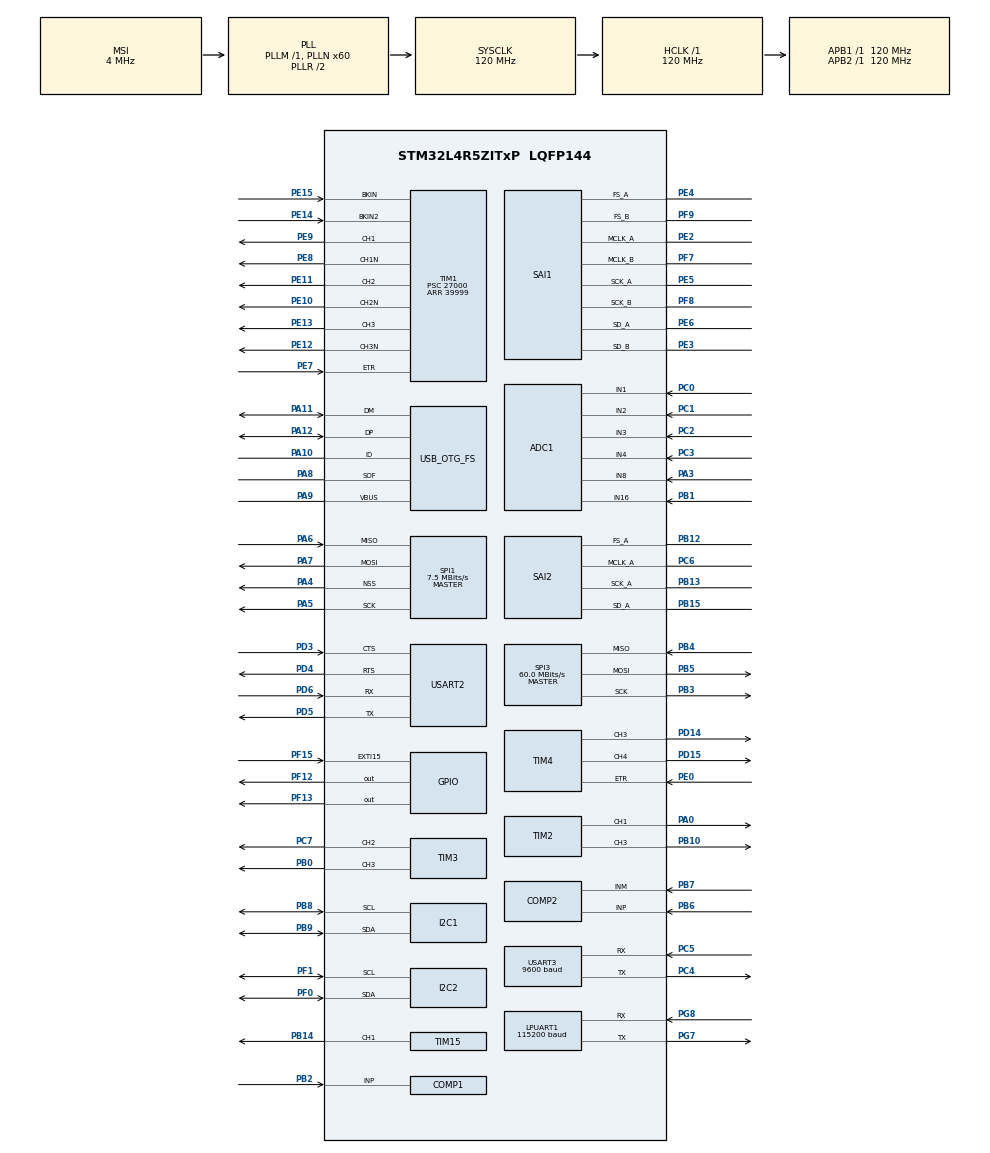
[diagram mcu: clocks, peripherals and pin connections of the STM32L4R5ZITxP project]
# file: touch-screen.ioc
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ADC1.Channel-0\#ChannelRegularConversion=ADC_CHANNEL_1
ADC1.NbrOfConversionFlag=1
ADC1.OffsetNumber-0\#ChannelRegularConversion=ADC_OFFSET_NONE
ADC1.Rank-0\#ChannelRegularConversion=1
ADC1.SamplingTime-0\#ChannelRegularConversion=ADC_SAMPLETIME_2CYCLES_5
ADC1.master=1
I2C1.Speed=100
I2C1.Timing=0x307075B1
I2C2.Timing=0x307075B1
LPUART1.BaudRate=115200
LPUART1.WordLength=UART_WORDLENGTH_8B
Mcu.Family=STM32L4
Mcu.Name=STM32L4R5ZITxP
Mcu.Package=LQFP144
NVIC.EXTI15_10_IRQn=true\:0\:0\:false\:false\:true\:true\:true\:true
NVIC.PriorityGroup=NVIC_PRIORITYGROUP_4
NVIC.TIM1_UP_TIM16_IRQn=true\:0\:0\:false\:false\:true\:true\:true\:true
NVIC.USART3_IRQn=true\:0\:0\:false\:false\:true\:true\:true\:true
PA0.Signal=S_TIM2_CH1
PA10.Mode=OTG/Dual_Role_Device
PA10.Signal=USB_OTG_FS_ID
PA11.Mode=OTG/Dual_Role_Device
PA11.Signal=USB_OTG_FS_DM
PA12.Mode=OTG/Dual_Role_Device
PA12.Signal=USB_OTG_FS_DP
PA13\ (JTMS/SWDIO).Mode=Serial_Wire
PA13\ (JTMS/SWDIO).Signal=SYS_JTMS-SWDIO
PA14\ (JTCK/SWCLK).Mode=Serial_Wire
PA14\ (JTCK/SWCLK).Signal=SYS_JTCK-SWCLK
PA3.Signal=ADCx_IN8
PA4.Mode=NSS_Signal_Hard_Output
PA4.Signal=SPI1_NSS
PA5.Mode=Full_Duplex_Master
PA5.Signal=SPI1_SCK
PA6.Mode=Full_Duplex_Master
PA6.Signal=SPI1_MISO
PA7.Mode=Full_Duplex_Master
PA7.Signal=SPI1_MOSI
PA8.Mode=Activate_SOF_FS
PA8.Signal=USB_OTG_FS_SOF
PA9.Mode=Activate_VBUS
PA9.Signal=USB_OTG_FS_VBUS
PB0.Signal=S_TIM3_CH3
PB1.Signal=ADCx_IN16
PB10.Signal=S_TIM2_CH3
PB12.Mode=SAI_A_MasterWithClock
PB12.Signal=SAI2_FS_A
PB13.Mode=SAI_A_MasterWithClock
PB13.Signal=SAI2_SCK_A
PB14.Signal=S_TIM15_CH1
PB15.Mode=SAI_A_MasterWithClock
PB15.Signal=SAI2_SD_A
PB2.Mode=INP
PB2.Signal=COMP1_INP
PB3\ (JTDO/TRACESWO).Mode=Full_Duplex_Master
PB3\ (JTDO/TRACESWO).Signal=SPI3_SCK
PB4\ (NJTRST).Mode=Full_Duplex_Master
PB4\ (NJTRST).Signal=SPI3_MISO
PB5.Mode=Full_Duplex_Master
PB5.Signal=SPI3_MOSI
PB6.Mode=INP
PB6.Signal=COMP2_INP
PB7.Mode=INM
PB7.Signal=COMP2_INM
PB8.GPIO_Pu=GPIO_PULLUP
PB8.Mode=I2C
PB8.Signal=I2C1_SCL
PB9.GPIO_Pu=GPIO_PULLUP
PB9.Mode=I2C
PB9.Signal=I2C1_SDA
PC0.Signal=ADCx_IN1
PC1.Signal=ADCx_IN2
PC13.Mode=SYS_WakeUp1
PC13.Signal=SYS_WKUP2
PC14-OSC32_IN\ (PC14).Mode=LSE-External-Oscillator
PC14-OSC32_IN\ (PC14).Signal=RCC_OSC32_IN
PC15-OSC32_OUT\ (PC15).Mode=LSE-External-Oscillator
PC15-OSC32_OUT\ (PC15).Signal=RCC_OSC32_OUT
PC2.Signal=ADCx_IN3
PC3.Signal=ADCx_IN4
PC4.Mode=Asynchronous
PC4.Signal=USART3_TX
PC5.Mode=Asynchronous
PC5.Signal=USART3_RX
PC6.Mode=SAI_A_MasterWithClock
PC6.Signal=SAI2_MCLK_A
PC7.Signal=S_TIM3_CH2
PD14.Signal=S_TIM4_CH3
PD15.Signal=S_TIM4_CH4
PD3.Mode=CTS_RTS
PD3.Signal=USART2_CTS
PD4.Mode=CTS_RTS
PD4.Signal=USART2_RTS
PD5.Mode=Asynchronous
PD5.Signal=USART2_TX
PD6.Mode=Asynchronous
PD6.Signal=USART2_RX
PE0.Signal=S_TIM4_ETR
PE10.Mode=PWM Generation2 CH2 CH2N
PE10.Signal=TIM1_CH2N
PE11.Signal=S_TIM1_CH2
PE12.Mode=PWM Generation3 CH3 CH3N
PE12.Signal=TIM1_CH3N
PE13.Signal=S_TIM1_CH3
PE14.Mode=Activate-Break-Input-2
PE14.Signal=TIM1_BKIN2
PE15.Mode=Activate-Break-Input
PE15.Signal=TIM1_BKIN
PE2.Mode=SAI_A_MasterWithClock
PE2.Signal=SAI1_MCLK_A
PE3.Mode=SAI_B_MasterWithClock
PE3.Signal=SAI1_SD_B
PE4.Mode=SAI_A_MasterWithClock
PE4.Signal=SAI1_FS_A
PE5.Mode=SAI_A_MasterWithClock
PE5.Signal=SAI1_SCK_A
PE6.Mode=SAI_A_MasterWithClock
PE6.Signal=SAI1_SD_A
PE7.Signal=S_TIM1_ETR
PE8.Mode=PWM Generation1 CH1 CH1N
PE8.Signal=TIM1_CH1N
PE9.Signal=S_TIM1_CH1
PF0.Mode=I2C
PF0.Signal=I2C2_SDA
PF1.Mode=I2C
PF1.Signal=I2C2_SCL
PF12.Signal=GPIO_Output
PF13.Signal=GPIO_Output
PF15.GPIO_ModeDefaultEXTI=GPIO_MODE_IT_FALLING
PF15.Signal=GPXTI15
PF7.Mode=SAI_B_MasterWithClock
PF7.Signal=SAI1_MCLK_B
PF8.Mode=SAI_B_MasterWithClock
PF8.Signal=SAI1_SCK_B
PF9.Mode=SAI_B_MasterWithClock
PF9.Signal=SAI1_FS_B
PG7.Mode=Asynchronous
PG7.Signal=LPUART1_TX
PG8.Mode=Asynchronous
PG8.Signal=LPUART1_RX
PH0-OSC_IN\ (PH0).Mode=HSE-External-Oscillator
PH0-OSC_IN\ (PH0).Signal=RCC_OSC_IN
PH1-OSC_OUT\ (PH1).Mode=HSE-External-Oscillator
PH1-OSC_OUT\ (PH1).Signal=RCC_OSC_OUT
ProjectManager.HeapSize=0x200
ProjectManager.StackSize=0x400
ProjectManager.TargetToolchain=STM32CubeIDE
RCC.ADCFreq_Value=48000000
RCC.AHBFreq_Value=120000000
RCC.APB1Freq_Value=120000000
RCC.APB1TimFreq_Value=120000000
RCC.APB2Freq_Value=120000000
RCC.APB2TimFreq_Value=120000000
RCC.CortexFreq_Value=120000000
RCC.HCLKFreq_Value=120000000
RCC.HSE_VALUE=8000000
RCC.HSI48_VALUE=48000000
RCC.HSI_VALUE=16000000
RCC.MSI_VALUE=4000000
RCC.PLLN=60
RCC.PLLSAI1N=24
RCC.SYSCLKFreq_VALUE=120000000
RCC.SYSCLKSource=RCC_SYSCLKSOURCE_PLLCLK
RCC.USBFreq_Value=48000000
RCC.VCOOutputFreq_Value=240000000
SAI1.InitProtocol-SAI_A_MasterWithClock=Enable
SAI1.Instance-SAI_A_MasterWithClock=SAI$Index_Block_A
SAI1.Instance-SAI_B_MasterWithClock=SAI$Index_Block_B
SAI1.MClockEnable-SAI_A_MasterWithClock=SAI_MASTERCLOCK_ENABLE
SAI1.MClockEnable-SAI_B_MasterWithClock=SAI_MASTERCLOCK_ENABLE
SAI1.Synchro-SAI_A_MasterWithClock=SAI_ASYNCHRONOUS
SAI1.Synchro-SAI_B_MasterWithClock=SAI_ASYNCHRONOUS
SAI1.VirtualMode-SAI_A_MasterWithClock=VM_MASTER
SAI1.VirtualMode-SAI_B_MasterWithClock=VM_MASTER
SAI1.VirtualProtocol-SAI_A_BASIC=VM_BASIC_PROTOCOL
SAI2.Instance-SAI_A_MasterWithClock=SAI$Index_Block_A
SAI2.MClockEnable-SAI_A_MasterWithClock=SAI_MASTERCLOCK_ENABLE
SAI2.Synchro-SAI_A_MasterWithClock=SAI_ASYNCHRONOUS
SAI2.VirtualMode-SAI_A_MasterWithClock=VM_MASTER
SH.ADCx_IN1.0=ADC1_IN1,IN1-Single-Ended
SH.ADCx_IN16.0=ADC1_IN16,IN16-Single-Ended
SH.ADCx_IN2.0=ADC1_IN2,IN2-Single-Ended
SH.ADCx_IN3.0=ADC1_IN3,IN3-Single-Ended
SH.ADCx_IN4.0=ADC1_IN4,IN4-Single-Ended
SH.ADCx_IN8.0=ADC1_IN8,IN8-Single-Ended
SH.S_TIM15_CH1.0=TIM15_CH1,PWM Generation1 CH1
SH.S_TIM1_CH1.0=TIM1_CH1,PWM Generation1 CH1 CH1N
SH.S_TIM1_CH2.0=TIM1_CH2,PWM Generation2 CH2 CH2N
SH.S_TIM1_CH3.0=TIM1_CH3,PWM Generation3 CH3 CH3N
SH.S_TIM1_ETR.0=TIM1_ETR,ETR-as-clearing-source
SH.S_TIM2_CH1.0=TIM2_CH1,PWM Generation1 CH1
SH.S_TIM2_CH3.0=TIM2_CH3,PWM Generation3 CH3
SH.S_TIM3_CH2.0=TIM3_CH2,PWM Generation2 CH2
SH.S_TIM3_CH3.0=TIM3_CH3,PWM Generation3 CH3
SH.S_TIM4_CH3.0=TIM4_CH3,PWM Generation3 CH3
SH.S_TIM4_CH4.0=TIM4_CH4,PWM Generation4 CH4
SH.S_TIM4_ETR.0=TIM4_ETR,ETR-as-clearing-source
SPI1.BaudRatePrescaler=SPI_BAUDRATEPRESCALER_16
SPI1.CalculateBaudRate=7.5 MBits/s
SPI1.DataSize=SPI_DATASIZE_8BIT
SPI1.Direction=SPI_DIRECTION_2LINES
SPI1.Mode=SPI_MODE_MASTER
SPI1.VirtualNSS=VM_NSSHARD
SPI1.VirtualType=VM_MASTER
SPI3.CalculateBaudRate=60.0 MBits/s
SPI3.Direction=SPI_DIRECTION_2LINES
SPI3.Mode=SPI_MODE_MASTER
SPI3.VirtualType=VM_MASTER
TIM1.Channel-PWM\ Generation1\ CH1\ CH1N=TIM_CHANNEL_1
TIM1.Channel-PWM\ Generation2\ CH2\ CH2N=TIM_CHANNEL_2
TIM1.Channel-PWM\ Generation3\ CH3\ CH3N=TIM_CHANNEL_3
TIM1.Period=39999
TIM1.Prescaler=27000
TIM15.Channel-PWM\ Generation1\ CH1=TIM_CHANNEL_1
TIM2.Channel-PWM\ Generation1\ CH1=TIM_CHANNEL_1
TIM2.Channel-PWM\ Generation3\ CH3=TIM_CHANNEL_3
TIM3.Channel-PWM\ Generation2\ CH2=TIM_CHANNEL_2
TIM3.Channel-PWM\ Generation3\ CH3=TIM_CHANNEL_3
TIM4.Channel-PWM\ Generation3\ CH3=TIM_CHANNEL_3
TIM4.Channel-PWM\ Generation4\ CH4=TIM_CHANNEL_4
USART2.VirtualMode-Asynchronous=VM_ASYNC
USART3.BaudRate=9600
USART3.VirtualMode-Asynchronous=VM_ASYNC
VP_COMP1_VS_VREFINT.Mode=VREFINT
VP_SAI1_VP_$IpInstance_SAIA_SAI_BASIC.Mode=SAI_A_BASIC
VP_TIM1_VS_ClockSourceINT.Mode=Internal
board=NUCLEO-L4R5ZI-P

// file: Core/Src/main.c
/* USER CODE BEGIN Header */
/**
 ******************************************************************************
 * @file           : main.c
 * @brief          : Main program body
 ******************************************************************************
 * @attention
 *
 * Copyright (c) 2024 STMicroelectronics.
 * All rights reserved.
 *
 * This software is licensed under terms that can be found in the LICENSE file
 * in the root directory of this software component.
 * If no LICENSE file comes with this software, it is provided AS-IS.
 *
 ******************************************************************************
 */
/* USER CODE END Header */
#include "main.h"

/* USER CODE BEGIN Includes */
#include "stdio.h"
#include "stdlib.h"
#include "string.h"
#include "foodorder.h"
#include "screen.h"
#include "touch.h"
/* USER CODE END Includes */

/* USER CODE BEGIN PD */
#define RX_BUFFER_SIZE 256
#define MAX_FOOD_ORDERS 5
#define SENSOR_ADDR 0x0C << 1 // Shift left for the HAL library
#define READ_LEN 2            // Start by reading the 16-bit content length
/* USER CODE END PD */

ADC_HandleTypeDef hadc1;

COMP_HandleTypeDef hcomp1;
COMP_HandleTypeDef hcomp2;

I2C_HandleTypeDef hi2c1;
I2C_HandleTypeDef hi2c2;

UART_HandleTypeDef hlpuart1;
UART_HandleTypeDef huart2;
UART_HandleTypeDef huart3;

SAI_HandleTypeDef hsai_BlockB1;
SAI_HandleTypeDef hsai_BlockA1;
SAI_HandleTypeDef hsai_BlockA2;

SPI_HandleTypeDef hspi1;
SPI_HandleTypeDef hspi3;

TIM_HandleTypeDef htim1;
TIM_HandleTypeDef htim2;
TIM_HandleTypeDef htim3;
TIM_HandleTypeDef htim4;
TIM_HandleTypeDef htim15;

/* USER CODE BEGIN PV */
char rxBuffer[RX_BUFFER_SIZE];
FoodOrder foodOrders[MAX_FOOD_ORDERS];
volatile uint16_t rxIndex = 0;
uint32_t i = 0;
/* USER CODE END PV */

void SystemClock_Config(void);
void PeriphCommonClock_Config(void);
static void MX_GPIO_Init(void);
static void MX_ADC1_Init(void);
static void MX_COMP1_Init(void);
static void MX_COMP2_Init(void);
static void MX_I2C1_Init(void);
static void MX_LPUART1_UART_Init(void);
static void MX_USART2_UART_Init(void);
static void MX_USART3_UART_Init(void);
static void MX_SAI1_Init(void);
static void MX_SAI2_Init(void);
static void MX_SPI1_Init(void);
static void MX_SPI3_Init(void);
static void MX_TIM1_Init(void);
static void MX_TIM2_Init(void);
static void MX_TIM3_Init(void);
static void MX_TIM4_Init(void);
static void MX_TIM15_Init(void);
static void MX_USB_OTG_FS_USB_Init(void);
static void MX_I2C2_Init(void);
/* USER CODE BEGIN PFP */
void processReceivedData(char *data);
static void uartSend(char *str);
/* USER CODE END PFP */

/* USER CODE BEGIN 0 */
void readTinyCodeData(void)
{
  uint8_t readBuffer[256]; // Buffer to store the read data
  uint16_t contentLength = 0;

  // First, read the content length
  HAL_StatusTypeDef status = HAL_I2C_Master_Receive(&hi2c2, SENSOR_ADDR, readBuffer, READ_LEN, HAL_MAX_DELAY);
  if (status != HAL_OK)
  {
    // Handle communication error
  }
  else
  {
    // If read is successful, parse the content length
    contentLength = readBuffer[0] | (readBuffer[1] << 8);
    if (contentLength == 0 ||  contentLength > 254)
    {
      return;
    }
    printf("content length %d\n", contentLength);
    if (contentLength > 0 && contentLength <= 254)
    {
      // Now, read the actual content based on the content length
      status = HAL_I2C_Master_Receive(&hi2c2, SENSOR_ADDR, readBuffer, contentLength + 2, HAL_MAX_DELAY);
      if (status != HAL_OK)
      {
        // Handle communication error
      }
      else
      {
        // Data is now in readBuffer[2] to readBuffer[contentLength+1], process it as needed
        // Remember to handle non-UTF-8 or other data safely
        for (int i = 0; i < contentLength; ++i)
        {
          printf("%c", readBuffer[2 + i]);
        }
        printf("\n");
      }
    }
    else
    {
      // No content or content length invalid
    }
  }
}
void HAL_TIM_PeriodElapsedCallback(TIM_HandleTypeDef *htim)
{
  	if(htim->Instance == TIM1){
  		  uartSend("LIST\n");
  		  HAL_UART_Receive_IT(&huart3, (uint8_t*)&rxBuffer[rxIndex], 1);
  	}
}
void HAL_UART_RxCpltCallback(UART_HandleTypeDef *huart)
{
  if (huart->Instance == USART3)
  {
    ++i;
  }
}

void processReceivedData(char *data)
{
  int totalOrders = atoi(data);
  data += 3;
  int processedOrders = 0;
  if (totalOrders == 0)
  {
    return;
  }
  for (int i = 0; i < MAX_FOOD_ORDERS; ++i)
  {
    FoodOrder_Init(&foodOrders[i]);
  }
  while (processedOrders < totalOrders)
  {
    foodOrders[processedOrders].id = atoi(data);
    data += 11;
    strcpy(foodOrders[processedOrders].name, data);
    while (*data != '\0')
    {
      ++data;
    }
    ++data;
    foodOrders[processedOrders].valid = 1;
    ++processedOrders;
  }
  for (int i = 0; i < processedOrders; ++i)
  {
    printf("Name: %s\r\n", foodOrders[i].name);
    printf("id: %d\r\n", foodOrders[i].id);
  }
}
static void uartSend(char *str)
{
	HAL_StatusTypeDef result = HAL_UART_Transmit(&huart3, (uint8_t *)str, strlen(str), 1000);
  if (HAL_OK != result) {
	  printf("USART send failed with code %d.\r\n", result);
  }
}
void HAL_GPIO_EXTI_Callback(uint16_t GPIO_Pin)
{
  touchHook(&hi2c1);
}
/* USER CODE END 0 */

int main(void)
{

  /* USER CODE BEGIN 1 */
  for (int i = 0; i < MAX_FOOD_ORDERS; ++i)
  {
    FoodOrder_Init(&foodOrders[i]);
  }
  /* USER CODE END 1 */

  /* MCU Configuration--------------------------------------------------------*/

  /* Reset of all peripherals, Initializes the Flash interface and the Systick. */
  HAL_Init();

  /* Configure the system clock */
  SystemClock_Config();

/* Configure the peripherals common clocks */
  PeriphCommonClock_Config();

  /* Initialize all configured peripherals */
  MX_GPIO_Init();
  MX_ADC1_Init();
  MX_COMP1_Init();
  MX_COMP2_Init();
  MX_I2C1_Init();
  MX_LPUART1_UART_Init();
  MX_USART2_UART_Init();
  MX_USART3_UART_Init();
  MX_SAI1_Init();
  MX_SAI2_Init();
  MX_SPI1_Init();
  MX_SPI3_Init();
  MX_TIM1_Init();
  MX_TIM2_Init();
  MX_TIM3_Init();
  MX_TIM4_Init();
  MX_TIM15_Init();
  MX_USB_OTG_FS_USB_Init();
  MX_I2C2_Init();
  /* USER CODE BEGIN 2 */
  HAL_TIM_Base_Start_IT(&htim1);
  initialize_screen(&hspi1);
  draw(&hspi1);
  initialize_touch(&hi2c1);

  /* USER CODE END 2 */

  /* Infinite loop */
  /* USER CODE BEGIN WHILE */
  while (1)
  {
    while (i > 0)
    {
      //		  printf("%c", rxBuffer[rxIndex]);
      if (rxBuffer[rxIndex] == '\n' || rxIndex >= RX_BUFFER_SIZE - 1 || rxBuffer[rxIndex] == '\r')
      {
        // Null-terminate the string
        rxBuffer[rxIndex] = '\0';

        // Process received data
        processReceivedData(rxBuffer);

        // Reset index
        rxIndex = 0;
      }
      else
      {
        // Increment index to receive the next byte
        rxIndex++;
      }
      // Prepare to receive the next byte
      HAL_UART_Receive_IT(&huart3, (uint8_t *)&rxBuffer[rxIndex], 1);

      --i;
    }
    readTinyCodeData();
    /* USER CODE END WHILE */

  }
}

void SystemClock_Config(void)
{
  RCC_OscInitTypeDef RCC_OscInitStruct = {0};
  RCC_ClkInitTypeDef RCC_ClkInitStruct = {0};

  /** Configure the main internal regulator output voltage
  */
  if (HAL_PWREx_ControlVoltageScaling(PWR_REGULATOR_VOLTAGE_SCALE1_BOOST) != HAL_OK)
  {
    Error_Handler();
  }

  /** Configure LSE Drive Capability
  */
  HAL_PWR_EnableBkUpAccess();
  __HAL_RCC_LSEDRIVE_CONFIG(RCC_LSEDRIVE_LOW);

  /** Initializes the RCC Oscillators according to the specified parameters
  * in the RCC_OscInitTypeDef structure.
  */
  RCC_OscInitStruct.OscillatorType = RCC_OSCILLATORTYPE_LSE|RCC_OSCILLATORTYPE_MSI;
  RCC_OscInitStruct.LSEState = RCC_LSE_ON;
  RCC_OscInitStruct.MSIState = RCC_MSI_ON;
  RCC_OscInitStruct.MSICalibrationValue = 0;
  RCC_OscInitStruct.MSIClockRange = RCC_MSIRANGE_6;
  RCC_OscInitStruct.PLL.PLLState = RCC_PLL_ON;
  RCC_OscInitStruct.PLL.PLLSource = RCC_PLLSOURCE_MSI;
  RCC_OscInitStruct.PLL.PLLM = 1;
  RCC_OscInitStruct.PLL.PLLN = 60;
  RCC_OscInitStruct.PLL.PLLP = RCC_PLLP_DIV2;
  RCC_OscInitStruct.PLL.PLLQ = RCC_PLLQ_DIV2;
  RCC_OscInitStruct.PLL.PLLR = RCC_PLLR_DIV2;
  if (HAL_RCC_OscConfig(&RCC_OscInitStruct) != HAL_OK)
  {
    Error_Handler();
  }

  /** Initializes the CPU, AHB and APB buses clocks
  */
  RCC_ClkInitStruct.ClockType = RCC_CLOCKTYPE_HCLK|RCC_CLOCKTYPE_SYSCLK
                              |RCC_CLOCKTYPE_PCLK1|RCC_CLOCKTYPE_PCLK2;
  RCC_ClkInitStruct.SYSCLKSource = RCC_SYSCLKSOURCE_PLLCLK;
  RCC_ClkInitStruct.AHBCLKDivider = RCC_SYSCLK_DIV1;
  RCC_ClkInitStruct.APB1CLKDivider = RCC_HCLK_DIV1;
  RCC_ClkInitStruct.APB2CLKDivider = RCC_HCLK_DIV1;

  if (HAL_RCC_ClockConfig(&RCC_ClkInitStruct, FLASH_LATENCY_5) != HAL_OK)
  {
    Error_Handler();
  }

  /** Enable MSI Auto calibration
  */
  HAL_RCCEx_EnableMSIPLLMode();
}

void PeriphCommonClock_Config(void)
{
  RCC_PeriphCLKInitTypeDef PeriphClkInit = {0};

  /** Initializes the peripherals clock
  */
  PeriphClkInit.PeriphClockSelection = RCC_PERIPHCLK_SAI1|RCC_PERIPHCLK_SAI2
                              |RCC_PERIPHCLK_USB|RCC_PERIPHCLK_ADC;
  PeriphClkInit.Sai1ClockSelection = RCC_SAI1CLKSOURCE_PLLSAI1;
  PeriphClkInit.Sai2ClockSelection = RCC_SAI2CLKSOURCE_PLLSAI1;
  PeriphClkInit.AdcClockSelection = RCC_ADCCLKSOURCE_PLLSAI1;
  PeriphClkInit.UsbClockSelection = RCC_USBCLKSOURCE_PLLSAI1;
  PeriphClkInit.PLLSAI1.PLLSAI1Source = RCC_PLLSOURCE_MSI;
  PeriphClkInit.PLLSAI1.PLLSAI1M = 1;
  PeriphClkInit.PLLSAI1.PLLSAI1N = 24;
  PeriphClkInit.PLLSAI1.PLLSAI1P = RCC_PLLP_DIV2;
  PeriphClkInit.PLLSAI1.PLLSAI1Q = RCC_PLLQ_DIV2;
  PeriphClkInit.PLLSAI1.PLLSAI1R = RCC_PLLR_DIV2;
  PeriphClkInit.PLLSAI1.PLLSAI1ClockOut = RCC_PLLSAI1_SAI1CLK|RCC_PLLSAI1_48M2CLK
                              |RCC_PLLSAI1_ADC1CLK;
  if (HAL_RCCEx_PeriphCLKConfig(&PeriphClkInit) != HAL_OK)
  {
    Error_Handler();
  }
}

static void MX_ADC1_Init(void)
{

  ADC_ChannelConfTypeDef sConfig = {0};

  /** Common config
  */
  hadc1.Instance = ADC1;
  hadc1.Init.ClockPrescaler = ADC_CLOCK_ASYNC_DIV1;
  hadc1.Init.Resolution = ADC_RESOLUTION_12B;
  hadc1.Init.DataAlign = ADC_DATAALIGN_RIGHT;
  hadc1.Init.ScanConvMode = ADC_SCAN_DISABLE;
  hadc1.Init.EOCSelection = ADC_EOC_SINGLE_CONV;
  hadc1.Init.LowPowerAutoWait = DISABLE;
  hadc1.Init.ContinuousConvMode = DISABLE;
  hadc1.Init.NbrOfConversion = 1;
  hadc1.Init.DiscontinuousConvMode = DISABLE;
  hadc1.Init.ExternalTrigConv = ADC_SOFTWARE_START;
  hadc1.Init.ExternalTrigConvEdge = ADC_EXTERNALTRIGCONVEDGE_NONE;
  hadc1.Init.DMAContinuousRequests = DISABLE;
  hadc1.Init.Overrun = ADC_OVR_DATA_PRESERVED;
  hadc1.Init.OversamplingMode = DISABLE;
  if (HAL_ADC_Init(&hadc1) != HAL_OK)
  {
    Error_Handler();
  }

  /** Configure Regular Channel
  */
  sConfig.Channel = ADC_CHANNEL_1;
  sConfig.Rank = ADC_REGULAR_RANK_1;
  sConfig.SamplingTime = ADC_SAMPLETIME_2CYCLES_5;
  sConfig.SingleDiff = ADC_SINGLE_ENDED;
  sConfig.OffsetNumber = ADC_OFFSET_NONE;
  sConfig.Offset = 0;
  if (HAL_ADC_ConfigChannel(&hadc1, &sConfig) != HAL_OK)
  {
    Error_Handler();
  }

}

static void MX_COMP1_Init(void)
{

  hcomp1.Instance = COMP1;
  hcomp1.Init.InvertingInput = COMP_INPUT_MINUS_VREFINT;
  hcomp1.Init.NonInvertingInput = COMP_INPUT_PLUS_IO2;
  hcomp1.Init.OutputPol = COMP_OUTPUTPOL_NONINVERTED;
  hcomp1.Init.Hysteresis = COMP_HYSTERESIS_NONE;
  hcomp1.Init.BlankingSrce = COMP_BLANKINGSRC_NONE;
  hcomp1.Init.Mode = COMP_POWERMODE_HIGHSPEED;
  hcomp1.Init.WindowMode = COMP_WINDOWMODE_DISABLE;
  hcomp1.Init.TriggerMode = COMP_TRIGGERMODE_NONE;
  if (HAL_COMP_Init(&hcomp1) != HAL_OK)
  {
    Error_Handler();
  }

}

static void MX_COMP2_Init(void)
{

  hcomp2.Instance = COMP2;
  hcomp2.Init.InvertingInput = COMP_INPUT_MINUS_IO2;
  hcomp2.Init.NonInvertingInput = COMP_INPUT_PLUS_IO2;
  hcomp2.Init.OutputPol = COMP_OUTPUTPOL_NONINVERTED;
  hcomp2.Init.Hysteresis = COMP_HYSTERESIS_NONE;
  hcomp2.Init.BlankingSrce = COMP_BLANKINGSRC_NONE;
  hcomp2.Init.Mode = COMP_POWERMODE_HIGHSPEED;
  hcomp2.Init.WindowMode = COMP_WINDOWMODE_DISABLE;
  hcomp2.Init.TriggerMode = COMP_TRIGGERMODE_NONE;
  if (HAL_COMP_Init(&hcomp2) != HAL_OK)
  {
    Error_Handler();
  }

}

static void MX_I2C1_Init(void)
{

  hi2c1.Instance = I2C1;
  hi2c1.Init.Timing = 0x307075B1;
  hi2c1.Init.OwnAddress1 = 0;
  hi2c1.Init.AddressingMode = I2C_ADDRESSINGMODE_7BIT;
  hi2c1.Init.DualAddressMode = I2C_DUALADDRESS_DISABLE;
  hi2c1.Init.OwnAddress2 = 0;
  hi2c1.Init.OwnAddress2Masks = I2C_OA2_NOMASK;
  hi2c1.Init.GeneralCallMode = I2C_GENERALCALL_DISABLE;
  hi2c1.Init.NoStretchMode = I2C_NOSTRETCH_DISABLE;
  if (HAL_I2C_Init(&hi2c1) != HAL_OK)
  {
    Error_Handler();
  }

  /** Configure Analogue filter
  */
  if (HAL_I2CEx_ConfigAnalogFilter(&hi2c1, I2C_ANALOGFILTER_ENABLE) != HAL_OK)
  {
    Error_Handler();
  }

  /** Configure Digital filter
  */
  if (HAL_I2CEx_ConfigDigitalFilter(&hi2c1, 0) != HAL_OK)
  {
    Error_Handler();
  }

}

static void MX_I2C2_Init(void)
{

  hi2c2.Instance = I2C2;
  hi2c2.Init.Timing = 0x307075B1;
  hi2c2.Init.OwnAddress1 = 0;
  hi2c2.Init.AddressingMode = I2C_ADDRESSINGMODE_7BIT;
  hi2c2.Init.DualAddressMode = I2C_DUALADDRESS_DISABLE;
  hi2c2.Init.OwnAddress2 = 0;
  hi2c2.Init.OwnAddress2Masks = I2C_OA2_NOMASK;
  hi2c2.Init.GeneralCallMode = I2C_GENERALCALL_DISABLE;
  hi2c2.Init.NoStretchMode = I2C_NOSTRETCH_DISABLE;
  if (HAL_I2C_Init(&hi2c2) != HAL_OK)
  {
    Error_Handler();
  }

  /** Configure Analogue filter
  */
  if (HAL_I2CEx_ConfigAnalogFilter(&hi2c2, I2C_ANALOGFILTER_ENABLE) != HAL_OK)
  {
    Error_Handler();
  }

  /** Configure Digital filter
  */
  if (HAL_I2CEx_ConfigDigitalFilter(&hi2c2, 0) != HAL_OK)
  {
    Error_Handler();
  }

}

static void MX_LPUART1_UART_Init(void)
{

  hlpuart1.Instance = LPUART1;
  hlpuart1.Init.BaudRate = 115200;
  hlpuart1.Init.WordLength = UART_WORDLENGTH_8B;
  hlpuart1.Init.StopBits = UART_STOPBITS_1;
  hlpuart1.Init.Parity = UART_PARITY_NONE;
  hlpuart1.Init.Mode = UART_MODE_TX_RX;
  hlpuart1.Init.HwFlowCtl = UART_HWCONTROL_NONE;
  hlpuart1.Init.OneBitSampling = UART_ONE_BIT_SAMPLE_DISABLE;
  hlpuart1.Init.ClockPrescaler = UART_PRESCALER_DIV1;
  hlpuart1.AdvancedInit.AdvFeatureInit = UART_ADVFEATURE_NO_INIT;
  hlpuart1.FifoMode = UART_FIFOMODE_DISABLE;
  if (HAL_UART_Init(&hlpuart1) != HAL_OK)
  {
    Error_Handler();
  }
  if (HAL_UARTEx_SetTxFifoThreshold(&hlpuart1, UART_TXFIFO_THRESHOLD_1_8) != HAL_OK)
  {
    Error_Handler();
  }
  if (HAL_UARTEx_SetRxFifoThreshold(&hlpuart1, UART_RXFIFO_THRESHOLD_1_8) != HAL_OK)
  {
    Error_Handler();
  }
  if (HAL_UARTEx_DisableFifoMode(&hlpuart1) != HAL_OK)
  {
    Error_Handler();
  }

}

static void MX_USART2_UART_Init(void)
{

  huart2.Instance = USART2;
  huart2.Init.BaudRate = 115200;
  huart2.Init.WordLength = UART_WORDLENGTH_8B;
  huart2.Init.StopBits = UART_STOPBITS_1;
  huart2.Init.Parity = UART_PARITY_NONE;
  huart2.Init.Mode = UART_MODE_TX_RX;
  huart2.Init.HwFlowCtl = UART_HWCONTROL_RTS_CTS;
  huart2.Init.OverSampling = UART_OVERSAMPLING_16;
  huart2.Init.OneBitSampling = UART_ONE_BIT_SAMPLE_DISABLE;
  huart2.Init.ClockPrescaler = UART_PRESCALER_DIV1;
  huart2.AdvancedInit.AdvFeatureInit = UART_ADVFEATURE_NO_INIT;
  if (HAL_UART_Init(&huart2) != HAL_OK)
  {
    Error_Handler();
  }
  if (HAL_UARTEx_SetTxFifoThreshold(&huart2, UART_TXFIFO_THRESHOLD_1_8) != HAL_OK)
  {
    Error_Handler();
  }
  if (HAL_UARTEx_SetRxFifoThreshold(&huart2, UART_RXFIFO_THRESHOLD_1_8) != HAL_OK)
  {
    Error_Handler();
  }
  if (HAL_UARTEx_DisableFifoMode(&huart2) != HAL_OK)
  {
    Error_Handler();
  }

}

static void MX_USART3_UART_Init(void)
{

  huart3.Instance = USART3;
  huart3.Init.BaudRate = 9600;
  huart3.Init.WordLength = UART_WORDLENGTH_8B;
  huart3.Init.StopBits = UART_STOPBITS_1;
  huart3.Init.Parity = UART_PARITY_NONE;
  huart3.Init.Mode = UART_MODE_TX_RX;
  huart3.Init.HwFlowCtl = UART_HWCONTROL_NONE;
  huart3.Init.OverSampling = UART_OVERSAMPLING_16;
  huart3.Init.OneBitSampling = UART_ONE_BIT_SAMPLE_DISABLE;
  huart3.Init.ClockPrescaler = UART_PRESCALER_DIV1;
  huart3.AdvancedInit.AdvFeatureInit = UART_ADVFEATURE_NO_INIT;
  if (HAL_UART_Init(&huart3) != HAL_OK)
  {
    Error_Handler();
  }
  if (HAL_UARTEx_SetTxFifoThreshold(&huart3, UART_TXFIFO_THRESHOLD_1_8) != HAL_OK)
  {
    Error_Handler();
  }
  if (HAL_UARTEx_SetRxFifoThreshold(&huart3, UART_RXFIFO_THRESHOLD_1_8) != HAL_OK)
  {
    Error_Handler();
  }
  if (HAL_UARTEx_DisableFifoMode(&huart3) != HAL_OK)
  {
    Error_Handler();
  }

}

static void MX_SAI1_Init(void)
{

  hsai_BlockB1.Instance = SAI1_Block_B;
  hsai_BlockB1.Init.Protocol = SAI_FREE_PROTOCOL;
  hsai_BlockB1.Init.AudioMode = SAI_MODEMASTER_TX;
  hsai_BlockB1.Init.DataSize = SAI_DATASIZE_8;
  hsai_BlockB1.Init.FirstBit = SAI_FIRSTBIT_MSB;
  hsai_BlockB1.Init.ClockStrobing = SAI_CLOCKSTROBING_FALLINGEDGE;
  hsai_BlockB1.Init.Synchro = SAI_ASYNCHRONOUS;
  hsai_BlockB1.Init.OutputDrive = SAI_OUTPUTDRIVE_DISABLE;
  hsai_BlockB1.Init.NoDivider = SAI_MASTERDIVIDER_ENABLE;
  hsai_BlockB1.Init.MckOverSampling = SAI_MCK_OVERSAMPLING_DISABLE;
  hsai_BlockB1.Init.FIFOThreshold = SAI_FIFOTHRESHOLD_EMPTY;
  hsai_BlockB1.Init.AudioFrequency = SAI_AUDIO_FREQUENCY_192K;
  hsai_BlockB1.Init.SynchroExt = SAI_SYNCEXT_DISABLE;
  hsai_BlockB1.Init.MonoStereoMode = SAI_STEREOMODE;
  hsai_BlockB1.Init.CompandingMode = SAI_NOCOMPANDING;
  hsai_BlockB1.Init.TriState = SAI_OUTPUT_NOTRELEASED;
  hsai_BlockB1.Init.PdmInit.Activation = DISABLE;
  hsai_BlockB1.Init.PdmInit.MicPairsNbr = 0;
  hsai_BlockB1.Init.PdmInit.ClockEnable = SAI_PDM_CLOCK1_ENABLE;
  hsai_BlockB1.FrameInit.FrameLength = 8;
  hsai_BlockB1.FrameInit.ActiveFrameLength = 1;
  hsai_BlockB1.FrameInit.FSDefinition = SAI_FS_STARTFRAME;
  hsai_BlockB1.FrameInit.FSPolarity = SAI_FS_ACTIVE_LOW;
  hsai_BlockB1.FrameInit.FSOffset = SAI_FS_FIRSTBIT;
  hsai_BlockB1.SlotInit.FirstBitOffset = 0;
  hsai_BlockB1.SlotInit.SlotSize = SAI_SLOTSIZE_DATASIZE;
  hsai_BlockB1.SlotInit.SlotNumber = 1;
  hsai_BlockB1.SlotInit.SlotActive = 0x00000000;
  if (HAL_SAI_Init(&hsai_BlockB1) != HAL_OK)
  {
    Error_Handler();
  }
  hsai_BlockA1.Instance = SAI1_Block_A;
  hsai_BlockA1.Init.AudioMode = SAI_MODEMASTER_TX;
  hsai_BlockA1.Init.Synchro = SAI_ASYNCHRONOUS;
  hsai_BlockA1.Init.OutputDrive = SAI_OUTPUTDRIVE_DISABLE;
  hsai_BlockA1.Init.NoDivider = SAI_MASTERDIVIDER_ENABLE;
  hsai_BlockA1.Init.FIFOThreshold = SAI_FIFOTHRESHOLD_EMPTY;
  hsai_BlockA1.Init.AudioFrequency = SAI_AUDIO_FREQUENCY_192K;
  hsai_BlockA1.Init.SynchroExt = SAI_SYNCEXT_DISABLE;
  hsai_BlockA1.Init.MonoStereoMode = SAI_STEREOMODE;
  hsai_BlockA1.Init.CompandingMode = SAI_NOCOMPANDING;
  hsai_BlockA1.Init.TriState = SAI_OUTPUT_NOTRELEASED;
  if (HAL_SAI_InitProtocol(&hsai_BlockA1, SAI_I2S_STANDARD, SAI_PROTOCOL_DATASIZE_16BIT, 2) != HAL_OK)
  {
    Error_Handler();
  }

}

static void MX_SAI2_Init(void)
{

  hsai_BlockA2.Instance = SAI2_Block_A;
  hsai_BlockA2.Init.Protocol = SAI_FREE_PROTOCOL;
  hsai_BlockA2.Init.AudioMode = SAI_MODEMASTER_TX;
  hsai_BlockA2.Init.DataSize = SAI_DATASIZE_8;
  hsai_BlockA2.Init.FirstBit = SAI_FIRSTBIT_MSB;
  hsai_BlockA2.Init.ClockStrobing = SAI_CLOCKSTROBING_FALLINGEDGE;
  hsai_BlockA2.Init.Synchro = SAI_ASYNCHRONOUS;
  hsai_BlockA2.Init.OutputDrive = SAI_OUTPUTDRIVE_DISABLE;
  hsai_BlockA2.Init.NoDivider = SAI_MASTERDIVIDER_ENABLE;
  hsai_BlockA2.Init.MckOverSampling = SAI_MCK_OVERSAMPLING_DISABLE;
  hsai_BlockA2.Init.FIFOThreshold = SAI_FIFOTHRESHOLD_EMPTY;
  hsai_BlockA2.Init.AudioFrequency = SAI_AUDIO_FREQUENCY_192K;
  hsai_BlockA2.Init.SynchroExt = SAI_SYNCEXT_DISABLE;
  hsai_BlockA2.Init.MonoStereoMode = SAI_STEREOMODE;
  hsai_BlockA2.Init.CompandingMode = SAI_NOCOMPANDING;
  hsai_BlockA2.Init.TriState = SAI_OUTPUT_NOTRELEASED;
  hsai_BlockA2.Init.PdmInit.Activation = DISABLE;
  hsai_BlockA2.Init.PdmInit.MicPairsNbr = 0;
  hsai_BlockA2.Init.PdmInit.ClockEnable = SAI_PDM_CLOCK1_ENABLE;
  hsai_BlockA2.FrameInit.FrameLength = 8;
  hsai_BlockA2.FrameInit.ActiveFrameLength = 1;
  hsai_BlockA2.FrameInit.FSDefinition = SAI_FS_STARTFRAME;
  hsai_BlockA2.FrameInit.FSPolarity = SAI_FS_ACTIVE_LOW;
  hsai_BlockA2.FrameInit.FSOffset = SAI_FS_FIRSTBIT;
  hsai_BlockA2.SlotInit.FirstBitOffset = 0;
  hsai_BlockA2.SlotInit.SlotSize = SAI_SLOTSIZE_DATASIZE;
  hsai_BlockA2.SlotInit.SlotNumber = 1;
  hsai_BlockA2.SlotInit.SlotActive = 0x00000000;
  if (HAL_SAI_Init(&hsai_BlockA2) != HAL_OK)
  {
    Error_Handler();
  }

}

static void MX_SPI1_Init(void)
{

  /* SPI1 parameter configuration*/
  hspi1.Instance = SPI1;
  hspi1.Init.Mode = SPI_MODE_MASTER;
  hspi1.Init.Direction = SPI_DIRECTION_2LINES;
  hspi1.Init.DataSize = SPI_DATASIZE_8BIT;
  hspi1.Init.CLKPolarity = SPI_POLARITY_LOW;
  hspi1.Init.CLKPhase = SPI_PHASE_1EDGE;
  hspi1.Init.NSS = SPI_NSS_HARD_OUTPUT;
  hspi1.Init.BaudRatePrescaler = SPI_BAUDRATEPRESCALER_16;
  hspi1.Init.FirstBit = SPI_FIRSTBIT_MSB;
  hspi1.Init.TIMode = SPI_TIMODE_DISABLE;
  hspi1.Init.CRCCalculation = SPI_CRCCALCULATION_DISABLE;
  hspi1.Init.CRCPolynomial = 7;
  hspi1.Init.CRCLength = SPI_CRC_LENGTH_DATASIZE;
  hspi1.Init.NSSPMode = SPI_NSS_PULSE_ENABLE;
  if (HAL_SPI_Init(&hspi1) != HAL_OK)
  {
    Error_Handler();
  }

}

static void MX_SPI3_Init(void)
{

  /* SPI3 parameter configuration*/
  hspi3.Instance = SPI3;
  hspi3.Init.Mode = SPI_MODE_MASTER;
  hspi3.Init.Direction = SPI_DIRECTION_2LINES;
  hspi3.Init.DataSize = SPI_DATASIZE_4BIT;
  hspi3.Init.CLKPolarity = SPI_POLARITY_LOW;
  hspi3.Init.CLKPhase = SPI_PHASE_1EDGE;
  hspi3.Init.NSS = SPI_NSS_SOFT;
  hspi3.Init.BaudRatePrescaler = SPI_BAUDRATEPRESCALER_2;
  hspi3.Init.FirstBit = SPI_FIRSTBIT_MSB;
  hspi3.Init.TIMode = SPI_TIMODE_DISABLE;
  hspi3.Init.CRCCalculation = SPI_CRCCALCULATION_DISABLE;
  hspi3.Init.CRCPolynomial = 7;
  hspi3.Init.CRCLength = SPI_CRC_LENGTH_DATASIZE;
  hspi3.Init.NSSPMode = SPI_NSS_PULSE_ENABLE;
  if (HAL_SPI_Init(&hspi3) != HAL_OK)
  {
    Error_Handler();
  }

}

static void MX_TIM1_Init(void)
{

  TIM_ClockConfigTypeDef sClockSourceConfig = {0};
  TIM_MasterConfigTypeDef sMasterConfig = {0};
  TIMEx_BreakInputConfigTypeDef sBreakInputConfig = {0};
  TIM_OC_InitTypeDef sConfigOC = {0};
  TIM_BreakDeadTimeConfigTypeDef sBreakDeadTimeConfig = {0};

  htim1.Instance = TIM1;
  htim1.Init.Prescaler = 27000;
  htim1.Init.CounterMode = TIM_COUNTERMODE_UP;
  htim1.Init.Period = 39999;
  htim1.Init.ClockDivision = TIM_CLOCKDIVISION_DIV1;
  htim1.Init.RepetitionCounter = 0;
  htim1.Init.AutoReloadPreload = TIM_AUTORELOAD_PRELOAD_DISABLE;
  if (HAL_TIM_Base_Init(&htim1) != HAL_OK)
  {
    Error_Handler();
  }
  sClockSourceConfig.ClockSource = TIM_CLOCKSOURCE_INTERNAL;
  if (HAL_TIM_ConfigClockSource(&htim1, &sClockSourceConfig) != HAL_OK)
  {
    Error_Handler();
  }
  if (HAL_TIM_PWM_Init(&htim1) != HAL_OK)
  {
    Error_Handler();
  }
  sMasterConfig.MasterOutputTrigger = TIM_TRGO_RESET;
  sMasterConfig.MasterOutputTrigger2 = TIM_TRGO2_RESET;
  sMasterConfig.MasterSlaveMode = TIM_MASTERSLAVEMODE_DISABLE;
  if (HAL_TIMEx_MasterConfigSynchronization(&htim1, &sMasterConfig) != HAL_OK)
  {
    Error_Handler();
  }
  sBreakInputConfig.Source = TIM_BREAKINPUTSOURCE_BKIN;
  sBreakInputConfig.Enable = TIM_BREAKINPUTSOURCE_ENABLE;
  sBreakInputConfig.Polarity = TIM_BREAKINPUTSOURCE_POLARITY_HIGH;
  if (HAL_TIMEx_ConfigBreakInput(&htim1, TIM_BREAKINPUT_BRK, &sBreakInputConfig) != HAL_OK)
  {
    Error_Handler();
  }
  if (HAL_TIMEx_ConfigBreakInput(&htim1, TIM_BREAKINPUT_BRK2, &sBreakInputConfig) != HAL_OK)
  {
    Error_Handler();
  }
  sConfigOC.OCMode = TIM_OCMODE_PWM1;
  sConfigOC.Pulse = 0;
  sConfigOC.OCPolarity = TIM_OCPOLARITY_HIGH;
  sConfigOC.OCNPolarity = TIM_OCNPOLARITY_HIGH;
  sConfigOC.OCFastMode = TIM_OCFAST_DISABLE;
  sConfigOC.OCIdleState = TIM_OCIDLESTATE_RESET;
  sConfigOC.OCNIdleState = TIM_OCNIDLESTATE_RESET;
  if (HAL_TIM_PWM_ConfigChannel(&htim1, &sConfigOC, TIM_CHANNEL_1) != HAL_OK)
  {
    Error_Handler();
  }
  if (HAL_TIM_PWM_ConfigChannel(&htim1, &sConfigOC, TIM_CHANNEL_2) != HAL_OK)
  {
    Error_Handler();
  }
  if (HAL_TIM_PWM_ConfigChannel(&htim1, &sConfigOC, TIM_CHANNEL_3) != HAL_OK)
  {
    Error_Handler();
  }
  sBreakDeadTimeConfig.OffStateRunMode = TIM_OSSR_ENABLE;
  sBreakDeadTimeConfig.OffStateIDLEMode = TIM_OSSI_ENABLE;
  sBreakDeadTimeConfig.LockLevel = TIM_LOCKLEVEL_OFF;
  sBreakDeadTimeConfig.DeadTime = 0;
  sBreakDeadTimeConfig.BreakState = TIM_BREAK_ENABLE;
  sBreakDeadTimeConfig.BreakPolarity = TIM_BREAKPOLARITY_HIGH;
  sBreakDeadTimeConfig.BreakFilter = 0;
  sBreakDeadTimeConfig.Break2State = TIM_BREAK2_ENABLE;
  sBreakDeadTimeConfig.Break2Polarity = TIM_BREAK2POLARITY_HIGH;
  sBreakDeadTimeConfig.Break2Filter = 0;
  sBreakDeadTimeConfig.AutomaticOutput = TIM_AUTOMATICOUTPUT_DISABLE;
  if (HAL_TIMEx_ConfigBreakDeadTime(&htim1, &sBreakDeadTimeConfig) != HAL_OK)
  {
    Error_Handler();
  }
  HAL_TIM_MspPostInit(&htim1);

}

static void MX_TIM2_Init(void)
{

  TIM_MasterConfigTypeDef sMasterConfig = {0};
  TIM_OC_InitTypeDef sConfigOC = {0};

  htim2.Instance = TIM2;
  htim2.Init.Prescaler = 0;
  htim2.Init.CounterMode = TIM_COUNTERMODE_UP;
  htim2.Init.Period = 4294967295;
  htim2.Init.ClockDivision = TIM_CLOCKDIVISION_DIV1;
  htim2.Init.AutoReloadPreload = TIM_AUTORELOAD_PRELOAD_DISABLE;
  if (HAL_TIM_PWM_Init(&htim2) != HAL_OK)
  {
    Error_Handler();
  }
  sMasterConfig.MasterOutputTrigger = TIM_TRGO_RESET;
  sMasterConfig.MasterSlaveMode = TIM_MASTERSLAVEMODE_DISABLE;
  if (HAL_TIMEx_MasterConfigSynchronization(&htim2, &sMasterConfig) != HAL_OK)
  {
    Error_Handler();
  }
  sConfigOC.OCMode = TIM_OCMODE_PWM1;
  sConfigOC.Pulse = 0;
  sConfigOC.OCPolarity = TIM_OCPOLARITY_HIGH;
  sConfigOC.OCFastMode = TIM_OCFAST_DISABLE;
  if (HAL_TIM_PWM_ConfigChannel(&htim2, &sConfigOC, TIM_CHANNEL_1) != HAL_OK)
  {
    Error_Handler();
  }
  if (HAL_TIM_PWM_ConfigChannel(&htim2, &sConfigOC, TIM_CHANNEL_3) != HAL_OK)
  {
    Error_Handler();
  }
  HAL_TIM_MspPostInit(&htim2);

}

static void MX_TIM3_Init(void)
{

  TIM_MasterConfigTypeDef sMasterConfig = {0};
  TIM_OC_InitTypeDef sConfigOC = {0};

  htim3.Instance = TIM3;
  htim3.Init.Prescaler = 0;
  htim3.Init.CounterMode = TIM_COUNTERMODE_UP;
  htim3.Init.Period = 65535;
  htim3.Init.ClockDivision = TIM_CLOCKDIVISION_DIV1;
  htim3.Init.AutoReloadPreload = TIM_AUTORELOAD_PRELOAD_DISABLE;
  if (HAL_TIM_PWM_Init(&htim3) != HAL_OK)
  {
    Error_Handler();
  }
  sMasterConfig.MasterOutputTrigger = TIM_TRGO_RESET;
  sMasterConfig.MasterSlaveMode = TIM_MASTERSLAVEMODE_DISABLE;
  if (HAL_TIMEx_MasterConfigSynchronization(&htim3, &sMasterConfig) != HAL_OK)
  {
    Error_Handler();
  }
  sConfigOC.OCMode = TIM_OCMODE_PWM1;
  sConfigOC.Pulse = 0;
  sConfigOC.OCPolarity = TIM_OCPOLARITY_HIGH;
  sConfigOC.OCFastMode = TIM_OCFAST_DISABLE;
  if (HAL_TIM_PWM_ConfigChannel(&htim3, &sConfigOC, TIM_CHANNEL_2) != HAL_OK)
  {
    Error_Handler();
  }
  if (HAL_TIM_PWM_ConfigChannel(&htim3, &sConfigOC, TIM_CHANNEL_3) != HAL_OK)
  {
    Error_Handler();
  }
  HAL_TIM_MspPostInit(&htim3);

}

static void MX_TIM4_Init(void)
{

  TIM_MasterConfigTypeDef sMasterConfig = {0};
  TIM_OC_InitTypeDef sConfigOC = {0};

  htim4.Instance = TIM4;
  htim4.Init.Prescaler = 0;
  htim4.Init.CounterMode = TIM_COUNTERMODE_UP;
  htim4.Init.Period = 65535;
  htim4.Init.ClockDivision = TIM_CLOCKDIVISION_DIV1;
  htim4.Init.AutoReloadPreload = TIM_AUTORELOAD_PRELOAD_DISABLE;
  if (HAL_TIM_PWM_Init(&htim4) != HAL_OK)
  {
    Error_Handler();
  }
  sMasterConfig.MasterOutputTrigger = TIM_TRGO_RESET;
  sMasterConfig.MasterSlaveMode = TIM_MASTERSLAVEMODE_DISABLE;
  if (HAL_TIMEx_MasterConfigSynchronization(&htim4, &sMasterConfig) != HAL_OK)
  {
    Error_Handler();
  }
  sConfigOC.OCMode = TIM_OCMODE_PWM1;
  sConfigOC.Pulse = 0;
  sConfigOC.OCPolarity = TIM_OCPOLARITY_HIGH;
  sConfigOC.OCFastMode = TIM_OCFAST_DISABLE;
  if (HAL_TIM_PWM_ConfigChannel(&htim4, &sConfigOC, TIM_CHANNEL_3) != HAL_OK)
  {
    Error_Handler();
  }
  if (HAL_TIM_PWM_ConfigChannel(&htim4, &sConfigOC, TIM_CHANNEL_4) != HAL_OK)
  {
    Error_Handler();
  }
  HAL_TIM_MspPostInit(&htim4);

}

static void MX_TIM15_Init(void)
{

  TIM_MasterConfigTypeDef sMasterConfig = {0};
  TIM_OC_InitTypeDef sConfigOC = {0};
  TIM_BreakDeadTimeConfigTypeDef sBreakDeadTimeConfig = {0};

  htim15.Instance = TIM15;
  htim15.Init.Prescaler = 0;
  htim15.Init.CounterMode = TIM_COUNTERMODE_UP;
  htim15.Init.Period = 65535;
  htim15.Init.ClockDivision = TIM_CLOCKDIVISION_DIV1;
  htim15.Init.RepetitionCounter = 0;
  htim15.Init.AutoReloadPreload = TIM_AUTORELOAD_PRELOAD_DISABLE;
  if (HAL_TIM_PWM_Init(&htim15) != HAL_OK)
  {
    Error_Handler();
  }
  sMasterConfig.MasterOutputTrigger = TIM_TRGO_RESET;
  sMasterConfig.MasterSlaveMode = TIM_MASTERSLAVEMODE_DISABLE;
  if (HAL_TIMEx_MasterConfigSynchronization(&htim15, &sMasterConfig) != HAL_OK)
  {
    Error_Handler();
  }
  sConfigOC.OCMode = TIM_OCMODE_PWM1;
  sConfigOC.Pulse = 0;
  sConfigOC.OCPolarity = TIM_OCPOLARITY_HIGH;
  sConfigOC.OCNPolarity = TIM_OCNPOLARITY_HIGH;
  sConfigOC.OCFastMode = TIM_OCFAST_DISABLE;
  sConfigOC.OCIdleState = TIM_OCIDLESTATE_RESET;
  sConfigOC.OCNIdleState = TIM_OCNIDLESTATE_RESET;
  if (HAL_TIM_PWM_ConfigChannel(&htim15, &sConfigOC, TIM_CHANNEL_1) != HAL_OK)
  {
    Error_Handler();
  }
  sBreakDeadTimeConfig.OffStateRunMode = TIM_OSSR_DISABLE;
  sBreakDeadTimeConfig.OffStateIDLEMode = TIM_OSSI_DISABLE;
  sBreakDeadTimeConfig.LockLevel = TIM_LOCKLEVEL_OFF;
  sBreakDeadTimeConfig.DeadTime = 0;
  sBreakDeadTimeConfig.BreakState = TIM_BREAK_DISABLE;
  sBreakDeadTimeConfig.BreakPolarity = TIM_BREAKPOLARITY_HIGH;
  sBreakDeadTimeConfig.AutomaticOutput = TIM_AUTOMATICOUTPUT_DISABLE;
  if (HAL_TIMEx_ConfigBreakDeadTime(&htim15, &sBreakDeadTimeConfig) != HAL_OK)
  {
    Error_Handler();
  }
  HAL_TIM_MspPostInit(&htim15);

}

static void MX_USB_OTG_FS_USB_Init(void)
{

}

static void MX_GPIO_Init(void)
{
  GPIO_InitTypeDef GPIO_InitStruct = {0};

  /* GPIO Ports Clock Enable */
  __HAL_RCC_GPIOE_CLK_ENABLE();
  __HAL_RCC_GPIOC_CLK_ENABLE();
  __HAL_RCC_GPIOF_CLK_ENABLE();
  __HAL_RCC_GPIOH_CLK_ENABLE();
  __HAL_RCC_GPIOA_CLK_ENABLE();
  __HAL_RCC_GPIOB_CLK_ENABLE();
  __HAL_RCC_GPIOD_CLK_ENABLE();
  __HAL_RCC_GPIOG_CLK_ENABLE();
  HAL_PWREx_EnableVddIO2();

  /*Configure GPIO pin Output Level */
  HAL_GPIO_WritePin(GPIOF, GPIO_PIN_12|GPIO_PIN_13, GPIO_PIN_RESET);

  /*Configure GPIO pins : PF12 PF13 */
  GPIO_InitStruct.Pin = GPIO_PIN_12|GPIO_PIN_13;
  GPIO_InitStruct.Mode = GPIO_MODE_OUTPUT_PP;
  GPIO_InitStruct.Pull = GPIO_NOPULL;
  GPIO_InitStruct.Speed = GPIO_SPEED_FREQ_LOW;
  HAL_GPIO_Init(GPIOF, &GPIO_InitStruct);

  /*Configure GPIO pin : PF15 */
  GPIO_InitStruct.Pin = GPIO_PIN_15;
  GPIO_InitStruct.Mode = GPIO_MODE_IT_FALLING;
  GPIO_InitStruct.Pull = GPIO_NOPULL;
  HAL_GPIO_Init(GPIOF, &GPIO_InitStruct);

  /*Configure GPIO pins : PA8 PA10 PA11 PA12 */
  GPIO_InitStruct.Pin = GPIO_PIN_8|GPIO_PIN_10|GPIO_PIN_11|GPIO_PIN_12;
  GPIO_InitStruct.Mode = GPIO_MODE_AF_PP;
  GPIO_InitStruct.Pull = GPIO_NOPULL;
  GPIO_InitStruct.Speed = GPIO_SPEED_FREQ_VERY_HIGH;
  GPIO_InitStruct.Alternate = GPIO_AF10_OTG_FS;
  HAL_GPIO_Init(GPIOA, &GPIO_InitStruct);

  /*Configure GPIO pin : PA9 */
  GPIO_InitStruct.Pin = GPIO_PIN_9;
  GPIO_InitStruct.Mode = GPIO_MODE_INPUT;
  GPIO_InitStruct.Pull = GPIO_NOPULL;
  HAL_GPIO_Init(GPIOA, &GPIO_InitStruct);

  /* EXTI interrupt init*/
  HAL_NVIC_SetPriority(EXTI15_10_IRQn, 0, 0);
  HAL_NVIC_EnableIRQ(EXTI15_10_IRQn);

}

/* USER CODE BEGIN 4 */
#ifdef __GNUC__
#define PUTCHAR_PROTOTYPE int __io_putchar(int ch)
#else
#define PUTCHAR_PROTOTYPE int fputc(int ch, FILE *f)
#endif /* __GNUC__ */
PUTCHAR_PROTOTYPE
{
  HAL_UART_Transmit(&hlpuart1, (uint8_t *)&ch, 1, 0xFFFF);
  return ch;
}

/* USER CODE END 4 */

void Error_Handler(void)
{
  __disable_irq();
  while (1)
  {
  }
}
